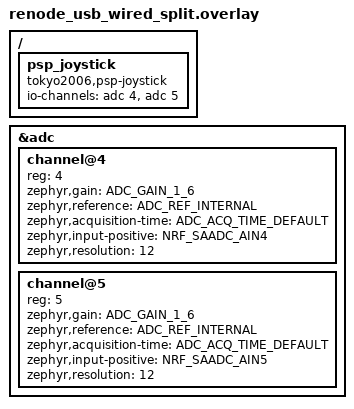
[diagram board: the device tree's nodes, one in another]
#include <zephyr/dt-bindings/adc/adc.h>
#include <zephyr/dt-bindings/adc/nrf-adc.h>

&adc {
    status = "okay";
    #address-cells = <1>;
    #size-cells = <0>;

    channel@4 {
        reg = <4>;
        zephyr,gain = "ADC_GAIN_1_6";
        zephyr,reference = "ADC_REF_INTERNAL";
        zephyr,acquisition-time = <ADC_ACQ_TIME_DEFAULT>;
        zephyr,input-positive = <NRF_SAADC_AIN4>;
        zephyr,resolution = <12>;
    };

    channel@5 {
        reg = <5>;
        zephyr,gain = "ADC_GAIN_1_6";
        zephyr,reference = "ADC_REF_INTERNAL";
        zephyr,acquisition-time = <ADC_ACQ_TIME_DEFAULT>;
        zephyr,input-positive = <NRF_SAADC_AIN5>;
        zephyr,resolution = <12>;
    };
};

/ {
    psp_joystick: psp_joystick {
        compatible = "tokyo2006,psp-joystick";
        io-channels = <&adc 4>, <&adc 5>;
        io-channel-names = "x", "y";
    };
};
